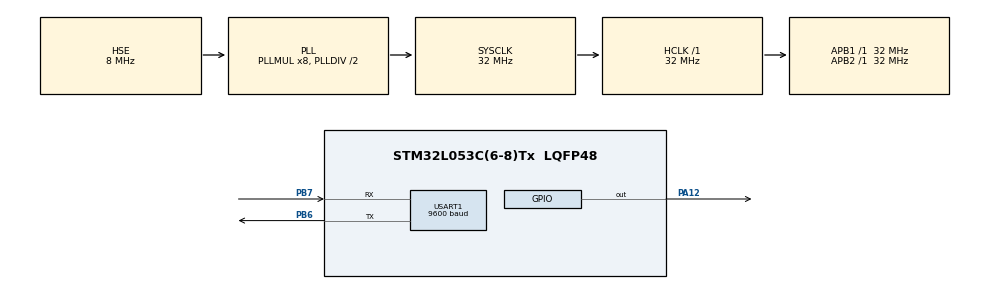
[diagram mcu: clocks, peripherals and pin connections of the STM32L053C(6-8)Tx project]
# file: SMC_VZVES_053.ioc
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Mcu.Family=STM32L0
Mcu.Name=STM32L053C(6-8)Tx
Mcu.Package=LQFP48
NVIC.TIM2_IRQn=true\:0\:0\:false\:false\:true\:true\:true
NVIC.USART1_IRQn=true\:0\:0\:false\:false\:true\:true\:true
PA12.Signal=GPIO_Output
PA13.Mode=Serial_Wire
PA13.Signal=SYS_SWDIO
PA14.Mode=Serial_Wire
PA14.Signal=SYS_SWCLK
PB6.Mode=Asynchronous
PB6.Signal=USART1_TX
PB7.Mode=Asynchronous
PB7.Signal=USART1_RX
PH0-OSC_IN.Mode=HSE-External-Oscillator
PH0-OSC_IN.Signal=RCC_OSC_IN
PH1-OSC_OUT.Mode=HSE-External-Oscillator
PH1-OSC_OUT.Signal=RCC_OSC_OUT
ProjectManager.HeapSize=0x200
ProjectManager.StackSize=0x400
ProjectManager.TargetToolchain=EWARM V8.32
RCC.AHBFreq_Value=32000000
RCC.APB1Freq_Value=32000000
RCC.APB1TimFreq_Value=32000000
RCC.APB2Freq_Value=32000000
RCC.APB2TimFreq_Value=32000000
RCC.HCLKFreq_Value=32000000
RCC.HSE_VALUE=8000000
RCC.HSI16_VALUE=16000000
RCC.HSI48_VALUE=48000000
RCC.HSI_VALUE=16000000
RCC.LSE_VALUE=32768
RCC.MSI_VALUE=2097000
RCC.PLLMUL=RCC_PLLMUL_8
RCC.PLLSourceVirtual=RCC_PLLSOURCE_HSE
RCC.SYSCLKFreq_VALUE=32000000
RCC.SYSCLKSource=RCC_SYSCLKSOURCE_PLLCLK
RCC.VCOOutputFreq_Value=64000000
TIM2.Period=999
TIM2.Prescaler=31
USART1.BaudRate=9600
USART1.VirtualMode-Asynchronous=VM_ASYNC
VP_CRC_VS_CRC.Mode=CRC_Activate
VP_RNG_VS_RNG.Mode=RNG_Activate
VP_TIM2_VS_ClockSourceINT.Mode=Internal
board=custom

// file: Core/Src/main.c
/* USER CODE BEGIN Header */
/**
  ******************************************************************************
  * @file           : main.c
  * @brief          : Main program body
  ******************************************************************************
  * @attention
  *
  * <h2><center>&copy; Copyright (c) 2025 STMicroelectronics.
  * All rights reserved.</center></h2>
  *
  * This software component is licensed by ST under BSD 3-Clause license,
  * the "License"; You may not use this file except in compliance with the
  * License. You may obtain a copy of the License at:
  *                        opensource.org/licenses/BSD-3-Clause
  *
  ******************************************************************************
  */
/* USER CODE END Header */
#include "main.h"

/* USER CODE BEGIN Includes */
#include <stdio.h>
#include <string.h>
#include "massaDriver.h"
#include "skc_usart_mass_driver.h"
/* USER CODE END Includes */

RNG_HandleTypeDef hrng;

TIM_HandleTypeDef htim2;

UART_HandleTypeDef huart1;

/* USER CODE BEGIN PV */
UsartDriver_TypeDef usartDriver;
RNG_HandleTypeDef hrng;
uint8_t sim;
MassDriver_TypeDef massDriver;
uint32_t counterNewSend[8];
uint32_t timeReloadeNewSend[8];

uint32_t counterMass;
uint32_t valueMass;
/* USER CODE END PV */

void SystemClock_Config(void);
static void MX_GPIO_Init(void);
static void MX_TIM2_Init(void);
static void MX_USART1_UART_Init(void);
static void MX_RNG_Init(void);

/* USER CODE BEGIN 0 */
    void HAL_UART_RxCpltCallback(UART_HandleTypeDef *huart)
{
          if(huart == &huart1)
          {
            reciveUsartSumbol(&usartDriver,sim);
            HAL_UART_Receive_IT(&huart1, &sim, 1);
          }
}

    void HAL_UART_TxCpltCallback(UART_HandleTypeDef *huart)
{
          if(huart == &huart1)
          {
           usartDriver.state = WAIT;
           GET_FRAME;

          }
}

void HAL_UART_ErrorCallback(UART_HandleTypeDef *huart){
          if(huart == &huart1)
          {
          GET_FRAME;
          usartDriver.state = WAIT;
          }

}

void HAL_TIM_PeriodElapsedCallback(TIM_HandleTypeDef *htim)
{
        if(htim->Instance == TIM2) //check if the interrupt comes from TIM1
        {

             usartDriver.timeWaitNewSymbol++;
             if(usartDriver.timeWaitNewSymbol >=100) usartDriver.len=0;

        }
}
/* USER CODE END 0 */

int main(void)
{

  /* MCU Configuration--------------------------------------------------------*/

  /* Reset of all peripherals, Initializes the Flash interface and the Systick. */
  HAL_Init();

  /* Configure the system clock */
  SystemClock_Config();

  /* Initialize all configured peripherals */
  MX_GPIO_Init();
  MX_TIM2_Init();
  MX_USART1_UART_Init();
  MX_RNG_Init();
  /* USER CODE BEGIN 2 */
  hrng.Instance = RNG;
  HAL_RNG_Init(&hrng);
  HAL_TIM_Base_Start_IT(&htim2);
  initMass(&massDriver,&hrng);
  SEND_FRAME;
  HAL_UART_Transmit_IT(&huart1, "VorG.LOADIND_DEVICE.\n",22);
  HAL_UART_Receive_IT(&huart1, (uint8_t*)&sim, 1);
  initUsartDriver(&usartDriver,&huart1);
  /* USER CODE END 2 */

  /* Infinite loop */
  while (1)
  {

    /* USER CODE BEGIN 3 */

    driverProcess(&usartDriver);

  }
  /* USER CODE END 3 */
}

void SystemClock_Config(void)
{
  RCC_OscInitTypeDef RCC_OscInitStruct = {0};
  RCC_ClkInitTypeDef RCC_ClkInitStruct = {0};
  RCC_PeriphCLKInitTypeDef PeriphClkInit = {0};

  /** Configure the main internal regulator output voltage
  */
  __HAL_PWR_VOLTAGESCALING_CONFIG(PWR_REGULATOR_VOLTAGE_SCALE1);
  /** Initializes the RCC Oscillators according to the specified parameters
  * in the RCC_OscInitTypeDef structure.
  */
  RCC_OscInitStruct.OscillatorType = RCC_OSCILLATORTYPE_HSE;
  RCC_OscInitStruct.HSEState = RCC_HSE_ON;
  RCC_OscInitStruct.PLL.PLLState = RCC_PLL_ON;
  RCC_OscInitStruct.PLL.PLLSource = RCC_PLLSOURCE_HSE;
  RCC_OscInitStruct.PLL.PLLMUL = RCC_PLLMUL_8;
  RCC_OscInitStruct.PLL.PLLDIV = RCC_PLLDIV_2;
  if (HAL_RCC_OscConfig(&RCC_OscInitStruct) != HAL_OK)
  {
    Error_Handler();
  }
  /** Initializes the CPU, AHB and APB buses clocks
  */
  RCC_ClkInitStruct.ClockType = RCC_CLOCKTYPE_HCLK|RCC_CLOCKTYPE_SYSCLK
                              |RCC_CLOCKTYPE_PCLK1|RCC_CLOCKTYPE_PCLK2;
  RCC_ClkInitStruct.SYSCLKSource = RCC_SYSCLKSOURCE_PLLCLK;
  RCC_ClkInitStruct.AHBCLKDivider = RCC_SYSCLK_DIV1;
  RCC_ClkInitStruct.APB1CLKDivider = RCC_HCLK_DIV1;
  RCC_ClkInitStruct.APB2CLKDivider = RCC_HCLK_DIV1;

  if (HAL_RCC_ClockConfig(&RCC_ClkInitStruct, FLASH_LATENCY_1) != HAL_OK)
  {
    Error_Handler();
  }
  PeriphClkInit.PeriphClockSelection = RCC_PERIPHCLK_USART1|RCC_PERIPHCLK_USB;
  PeriphClkInit.Usart1ClockSelection = RCC_USART1CLKSOURCE_PCLK2;
  PeriphClkInit.UsbClockSelection = RCC_USBCLKSOURCE_PLL;
  if (HAL_RCCEx_PeriphCLKConfig(&PeriphClkInit) != HAL_OK)
  {
    Error_Handler();
  }
}

static void MX_RNG_Init(void)
{

  hrng.Instance = RNG;
  if (HAL_RNG_Init(&hrng) != HAL_OK)
  {
    Error_Handler();
  }

}

static void MX_TIM2_Init(void)
{

  TIM_ClockConfigTypeDef sClockSourceConfig = {0};
  TIM_MasterConfigTypeDef sMasterConfig = {0};

  htim2.Instance = TIM2;
  htim2.Init.Prescaler = 31;
  htim2.Init.CounterMode = TIM_COUNTERMODE_UP;
  htim2.Init.Period = 999;
  htim2.Init.ClockDivision = TIM_CLOCKDIVISION_DIV1;
  htim2.Init.AutoReloadPreload = TIM_AUTORELOAD_PRELOAD_DISABLE;
  if (HAL_TIM_Base_Init(&htim2) != HAL_OK)
  {
    Error_Handler();
  }
  sClockSourceConfig.ClockSource = TIM_CLOCKSOURCE_INTERNAL;
  if (HAL_TIM_ConfigClockSource(&htim2, &sClockSourceConfig) != HAL_OK)
  {
    Error_Handler();
  }
  sMasterConfig.MasterOutputTrigger = TIM_TRGO_RESET;
  sMasterConfig.MasterSlaveMode = TIM_MASTERSLAVEMODE_DISABLE;
  if (HAL_TIMEx_MasterConfigSynchronization(&htim2, &sMasterConfig) != HAL_OK)
  {
    Error_Handler();
  }

}

static void MX_USART1_UART_Init(void)
{

  huart1.Instance = USART1;
  huart1.Init.BaudRate = 19200;
  huart1.Init.WordLength = UART_WORDLENGTH_8B;
  huart1.Init.StopBits = UART_STOPBITS_1;
  huart1.Init.Parity = UART_PARITY_NONE;
  huart1.Init.Mode = UART_MODE_TX_RX;
  huart1.Init.HwFlowCtl = UART_HWCONTROL_NONE;
  huart1.Init.OverSampling = UART_OVERSAMPLING_16;
  huart1.Init.OneBitSampling = UART_ONE_BIT_SAMPLE_DISABLE;
  huart1.AdvancedInit.AdvFeatureInit = UART_ADVFEATURE_NO_INIT;
  if (HAL_UART_Init(&huart1) != HAL_OK)
  {
    Error_Handler();
  }

}

static void MX_GPIO_Init(void)
{
  GPIO_InitTypeDef GPIO_InitStruct = {0};

  /* GPIO Ports Clock Enable */
  __HAL_RCC_GPIOH_CLK_ENABLE();
  __HAL_RCC_GPIOA_CLK_ENABLE();
  __HAL_RCC_GPIOB_CLK_ENABLE();

  /*Configure GPIO pin Output Level */
  HAL_GPIO_WritePin(GPIOA, GPIO_PIN_12, GPIO_PIN_RESET);

  /*Configure GPIO pin : PA12 */
  GPIO_InitStruct.Pin = GPIO_PIN_12;
  GPIO_InitStruct.Mode = GPIO_MODE_OUTPUT_PP;
  GPIO_InitStruct.Pull = GPIO_NOPULL;
  GPIO_InitStruct.Speed = GPIO_SPEED_FREQ_LOW;
  HAL_GPIO_Init(GPIOA, &GPIO_InitStruct);

}

void Error_Handler(void)
{
  __disable_irq();
  while (1)
  {
  }
}

/************************ (C) COPYRIGHT STMicroelectronics *****END OF FILE****/
